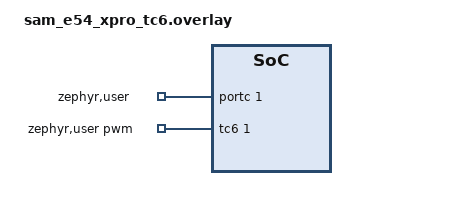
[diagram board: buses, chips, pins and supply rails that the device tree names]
/*
 * Copyright (c) 2025-2026 Microchip Technology Inc.
 * SPDX-License-Identifier: Apache-2.0
 */

/* connect PB17 to PC01 */

#define PWM_NODE     tc6
#define PWM_PINCTRL  tc6_pwm_default
#include "mchp_pwm_loopback_support.dtsi"

/ {
	zephyr,user {
		pwms = <&tc6 1 PWM_MSEC(1) 0>;
		gpios = <&portc 1 GPIO_ACTIVE_HIGH>;
	};
};

&portc {
	status = "okay";
};

&pinctrl {
	tc6_pwm_default: tc6_pwm_default {
		group1 {
			pinmux = <PB17E_TC6_WO1>;
		};
	};
};
